# R7FA6M5BH register map
Vendor: Renesas Electronics Corporation; Series: RA6; File version: 1.20.01
CPU: CM33 r0p4, little endian, MPU, FPU, VTOR, 4 interrupt priority bits, 96 interrupts
Registers are 32-bit, read-write, reset 0x0 unless marked. A register's access mark holds for its fields unless they carry their own. Offsets are from the block's base; [hi:lo] are bit positions; {n}, {i} and the like mark numbered series; 'fields as' and 'values as' point back to an identical list.

## CANFD (part 2 of 2)
Base 0x400B0000
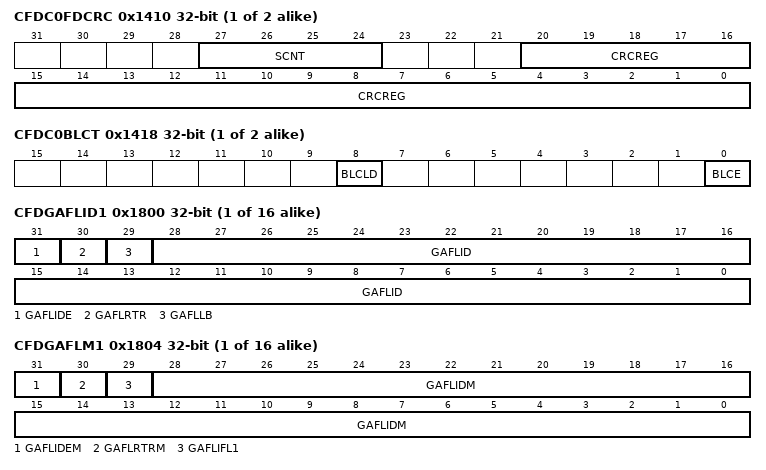
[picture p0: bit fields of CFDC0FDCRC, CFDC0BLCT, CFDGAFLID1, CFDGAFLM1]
{0x1410+0x20*i} CFDC{i}FDCRC (i=0..1) — Channel {i} CANFD CRC Register
  [27:24] SCNT ro — Stuff bit count
  [20:0] CRCREG ro — CRC Register value
{0x1418+0x20*i} CFDC{i}BLCT (i=0..1) — Channel {i} Bus Load Control Register
  [8] BLCLD wo — BUS Load Counter Load
  [0] BLCE — Bus Load Counter Enable
    0=Bus load counter disable; 1=Bus load counter enable
{0x141C+0x20*i} CFDC{i}BLSTS (i=0..1) — Channel {i} Bus Load Status Register
  [31:3] BLC ro — Bus Load Counter
{0x17F0+0x10*i} CFDGAFLID{i} (i=1..16) — Global Acceptance Filter List ID Registers
  [31] GAFLIDE — Global Acceptance Filter List Entry IDE Field
    0=Standard identifier of rule entry ID is valid for acceptance filtering; 1=Extended identifier of rule entry ID is valid for acceptance filtering
  [30] GAFLRTR — Global Acceptance Filter List Entry RTR Field
    0=Data frame; 1=Remote frame
  [29] GAFLLB — Global Acceptance Filter List Entry Loopback Configuration
    0=Global Acceptance Filter List entry ID for acceptance filtering with attribute RX; 1=Global Acceptance Filter List entry ID for acceptance filtering with attribute TX
  [28:0] GAFLID — Global Acceptance Filter List Entry ID Field
{0x17F4+0x10*i} CFDGAFLM{i} (i=1..16) — Global Acceptance Filter List Mask Registers
  [31] GAFLIDEM — Global Acceptance Filter List IDE Mask
    0=IDE bit is not used for ID matching; 1=IDE bit is used for ID matching
  [30] GAFLRTRM — Global Acceptance Filter List Entry RTR Mask
    0=RTR bit is not used for ID matching; 1=RTR bit is used for ID matching
  [29] GAFLIFL1 — Global Acceptance Filter List Information Label 1
  [28:0] GAFLIDM — Global Acceptance Filter List ID Mask Field
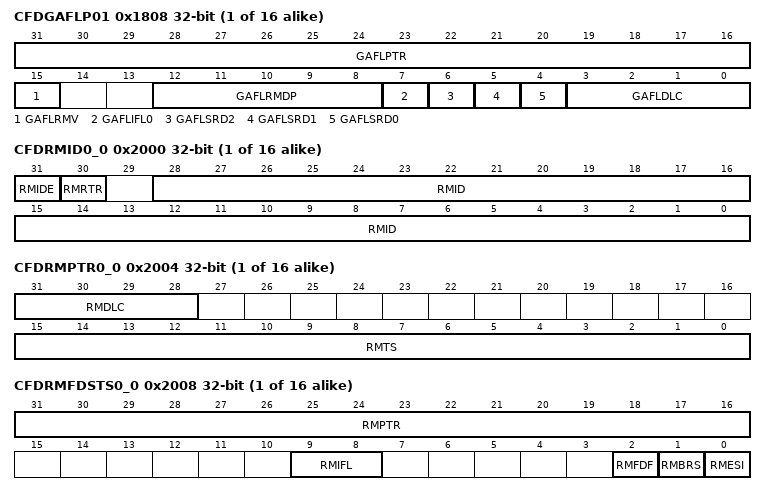
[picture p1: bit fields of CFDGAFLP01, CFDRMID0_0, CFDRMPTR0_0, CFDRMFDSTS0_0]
{0x17F8+0x10*i} CFDGAFLP0{i} (i=1..16) — Global Acceptance Filter List Pointer 0 Registers
  [31:16] GAFLPTR — Global Acceptance Filter List Pointer
  [15] GAFLRMV — Global Acceptance Filter List RX Message Buffer Valid
    0=Single message buffer direction pointer is invalid; 1=Single message buffer direction pointer is valid
  [12:8] GAFLRMDP — Global Acceptance Filter List RX Message Buffer Direction Pointer
  [7] GAFLIFL0 — Global Acceptance Filter List Information Label 0
  [6] GAFLSRD2 — Global Acceptance Filter List Select Routing Destination 2
    0=Routing target is CFIFO2; 1=Routing target is TX Queue 2 instead of CFIFO2
  [5] GAFLSRD1 — Global Acceptance Filter List Select Routing Destination 1
    0=Routing target is CFIFO1; 1=Routing target is TX Queue 1 instead of CFIFO1
  [4] GAFLSRD0 — Global Acceptance Filter List Select Routing Destination 0
    0=Routing target is CFIFO0; 1=Routing target is TX Queue 0 instead of CFIFO0
  [3:0] GAFLDLC — Global Acceptance Filter List DLC Field
{0x17FC+0x10*i} CFDGAFLP1{i} (i=1..16) — Global Acceptance Filter List Pointer 1 Registers
  [13:0] GAFLFDP — Global Acceptance Filter List FIFO Direction Pointer
{0x2000+0x80*i} CFDRMID{i}_0 (i=0..15) ro — RX Message Buffer ID Register {i} Channel 0
  [31] RMIDE — RX Message Buffer IDE Bit
    0=STD-ID is stored; 1=EXT-ID is stored
  [30] RMRTR — RX Message Buffer RTR Bit
    0=Data frame; 1=Remote frame
  [28:0] RMID — RX Message Buffer ID Field
{0x2004+0x80*i} CFDRMPTR{i}_0 (i=0..15) ro — RX Message Buffer Pointer Register {i} Channel 0
  [31:28] RMDLC — RX Message Buffer DLC Field
  [15:0] RMTS — RX Message Buffer Timestamp Field
{0x2008+0x80*i} CFDRMFDSTS{i}_0 (i=0..15) ro — RX Message Buffer CAN-FD Status Register {i} Channel 0
  [31:16] RMPTR — RX Message Buffer Pointer Field
  [9:8] RMIFL — RX Message Buffer Information Label Field
  [2] RMFDF — CAN FD Format bit
    0=Non CAN-FD frame received; 1=CAN-FD frame received
  [1] RMBRS — Bit Rate Switch bit
    0=CAN-FD frame received with no bit rate switch; 1=CAN-FD frame received with bit rate switch
  [0] RMESI — Error State Indicator bit
    0=CAN-FD frame received from error active node; 1=CAN-FD frame received from error passive node
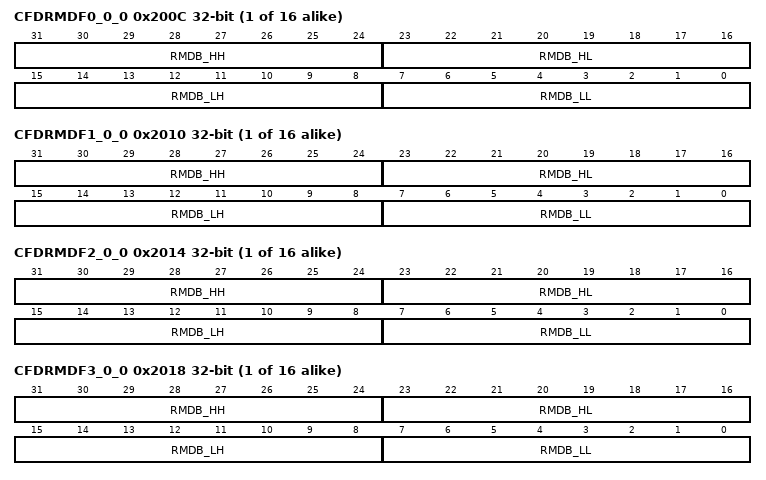
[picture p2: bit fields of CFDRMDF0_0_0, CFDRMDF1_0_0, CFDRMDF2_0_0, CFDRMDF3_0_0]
{0x200C+0x80*i} CFDRMDF0_{i}_0 (i=0..15) ro — RX Message Buffer Data Field 0 Register {i} Channel 0
  [31:24] RMDB_HH — RX Message Buffer Data Byte 3
  [23:16] RMDB_HL — RX Message Buffer Data Byte 2
  [15:8] RMDB_LH — RX Message Buffer Data Byte 1
  [7:0] RMDB_LL — RX Message Buffer Data Byte 0
{0x2010+0x80*i} CFDRMDF1_{i}_0 (i=0..15) ro — RX Message Buffer Data Field 1 Register {i} Channel 0
  [31:24] RMDB_HH — RX Message Buffer Data Byte 7
  [23:16] RMDB_HL — RX Message Buffer Data Byte 6
  [15:8] RMDB_LH — RX Message Buffer Data Byte 5
  [7:0] RMDB_LL — RX Message Buffer Data Byte 4
{0x2014+0x80*i} CFDRMDF2_{i}_0 (i=0..15) ro — RX Message Buffer Data Field 2 Register {i} Channel 0
  [31:24] RMDB_HH — RX Message Buffer Data Byte 11
  [23:16] RMDB_HL — RX Message Buffer Data Byte 10
  [15:8] RMDB_LH — RX Message Buffer Data Byte 9
  [7:0] RMDB_LL — RX Message Buffer Data Byte 8
{0x2018+0x80*i} CFDRMDF3_{i}_0 (i=0..15) ro — RX Message Buffer Data Field 3 Register {i} Channel 0
  [31:24] RMDB_HH — RX Message Buffer Data Byte 15
  [23:16] RMDB_HL — RX Message Buffer Data Byte 14
  [15:8] RMDB_LH — RX Message Buffer Data Byte 13
  [7:0] RMDB_LL — RX Message Buffer Data Byte 12
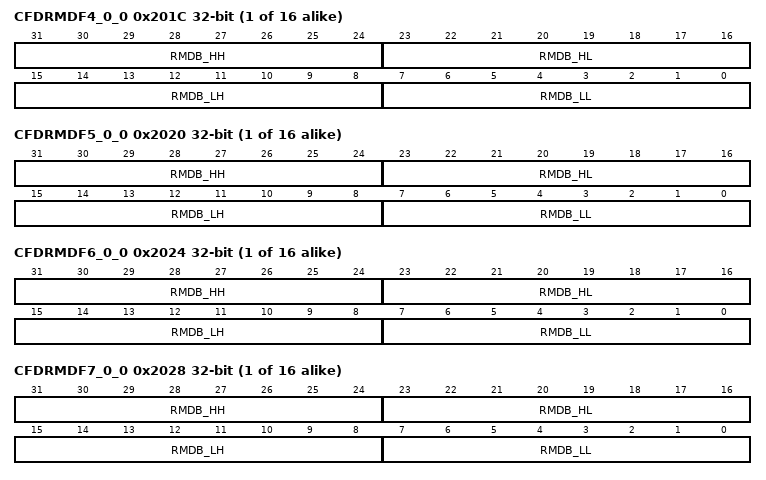
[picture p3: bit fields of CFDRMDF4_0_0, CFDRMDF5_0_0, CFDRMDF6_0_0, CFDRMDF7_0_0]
{0x201C+0x80*i} CFDRMDF4_{i}_0 (i=0..15) ro — RX Message Buffer Data Field 4 Register {i} Channel 0
  [31:24] RMDB_HH — RX Message Buffer Data Byte 19
  [23:16] RMDB_HL — RX Message Buffer Data Byte 18
  [15:8] RMDB_LH — RX Message Buffer Data Byte 17
  [7:0] RMDB_LL — RX Message Buffer Data Byte 16
{0x2020+0x80*i} CFDRMDF5_{i}_0 (i=0..15) ro — RX Message Buffer Data Field 5 Register {i} Channel 0
  [31:24] RMDB_HH — RX Message Buffer Data Byte 23
  [23:16] RMDB_HL — RX Message Buffer Data Byte 22
  [15:8] RMDB_LH — RX Message Buffer Data Byte 21
  [7:0] RMDB_LL — RX Message Buffer Data Byte 20
{0x2024+0x80*i} CFDRMDF6_{i}_0 (i=0..15) ro — RX Message Buffer Data Field 6 Register {i} Channel 0
  [31:24] RMDB_HH — RX Message Buffer Data Byte 27
  [23:16] RMDB_HL — RX Message Buffer Data Byte 26
  [15:8] RMDB_LH — RX Message Buffer Data Byte 25
  [7:0] RMDB_LL — RX Message Buffer Data Byte 24
{0x2028+0x80*i} CFDRMDF7_{i}_0 (i=0..15) ro — RX Message Buffer Data Field 7 Register {i} Channel 0
  [31:24] RMDB_HH — RX Message Buffer Data Byte 30
  [23:16] RMDB_HL — RX Message Buffer Data Byte 29
  [15:8] RMDB_LH — RX Message Buffer Data Byte 28
  [7:0] RMDB_LL — RX Message Buffer Data Byte 27
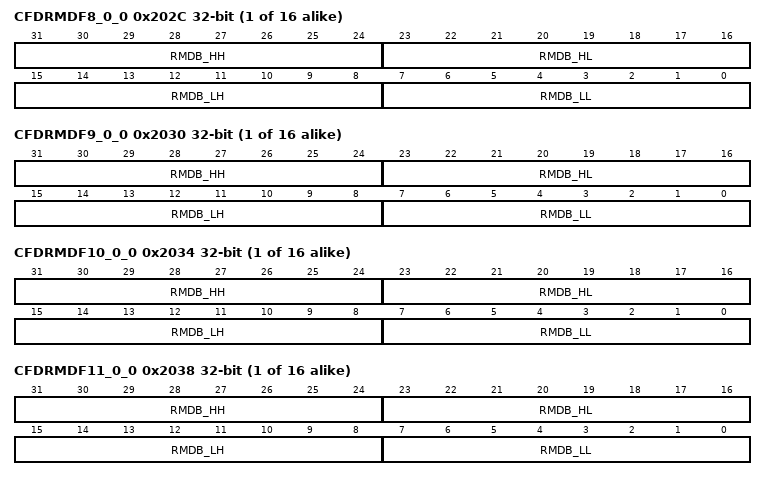
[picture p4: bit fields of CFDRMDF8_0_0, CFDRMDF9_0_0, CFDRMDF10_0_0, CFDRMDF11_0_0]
{0x202C+0x80*i} CFDRMDF8_{i}_0 (i=0..15) ro — RX Message Buffer Data Field 8 Register {i} Channel 0
  [31:24] RMDB_HH — RX Message Buffer Data Byte ((p * 4) + 3)
  [23:16] RMDB_HL — RX Message Buffer Data Byte ((p * 4) + 2)
  [15:8] RMDB_LH — RX Message Buffer Data Byte ((p * 4) + 1)
  [7:0] RMDB_LL — RX Message Buffer Data Byte (p * 4)
{0x2030+0x80*i} CFDRMDF9_{i}_0 (i=0..15) ro — RX Message Buffer Data Field 9 Register {i} Channel 0
  [31:24] RMDB_HH — RX Message Buffer Data Byte 39
  [23:16] RMDB_HL — RX Message Buffer Data Byte 38
  [15:8] RMDB_LH — RX Message Buffer Data Byte 37
  [7:0] RMDB_LL — RX Message Buffer Data Byte 36
{0x2034+0x80*i} CFDRMDF10_{i}_0 (i=0..15) ro — RX Message Buffer Data Field 10 Register {i} Channel 0
  [31:24] RMDB_HH — RX Message Buffer Data Byte 43
  [23:16] RMDB_HL — RX Message Buffer Data Byte 42
  [15:8] RMDB_LH — RX Message Buffer Data Byte 41
  [7:0] RMDB_LL — RX Message Buffer Data Byte 40
{0x2038+0x80*i} CFDRMDF11_{i}_0 (i=0..15) ro — RX Message Buffer Data Field 11 Register {i} Channel 0
  [31:24] RMDB_HH — RX Message Buffer Data Byte 47
  [23:16] RMDB_HL — RX Message Buffer Data Byte 46
  [15:8] RMDB_LH — RX Message Buffer Data Byte 45
  [7:0] RMDB_LL — RX Message Buffer Data Byte 44
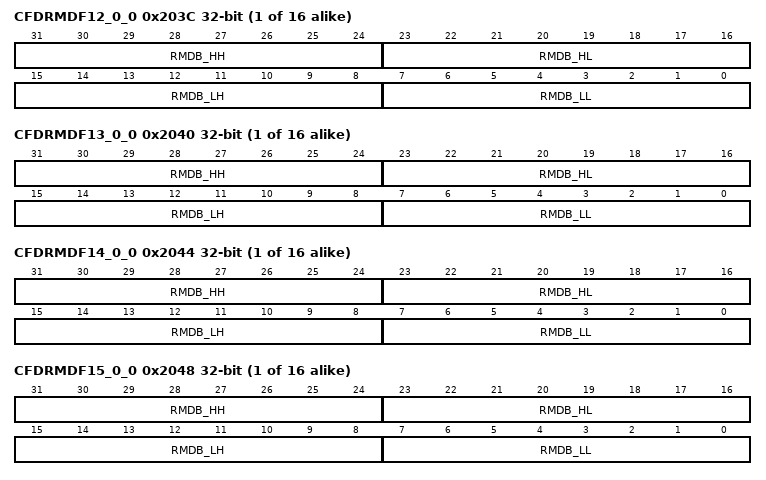
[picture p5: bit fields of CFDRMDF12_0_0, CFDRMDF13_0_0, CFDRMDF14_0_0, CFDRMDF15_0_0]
{0x203C+0x80*i} CFDRMDF12_{i}_0 (i=0..15) ro — RX Message Buffer Data Field 12 Register {i} Channel 0
  [31:24] RMDB_HH — RX Message Buffer Data Byte 51
  [23:16] RMDB_HL — RX Message Buffer Data Byte 50
  [15:8] RMDB_LH — RX Message Buffer Data Byte 49
  [7:0] RMDB_LL — RX Message Buffer Data Byte 48
{0x2040+0x80*i} CFDRMDF13_{i}_0 (i=0..15) ro — RX Message Buffer Data Field 13 Register {i} Channel 0
  [31:24] RMDB_HH — RX Message Buffer Data Byte 55
  [23:16] RMDB_HL — RX Message Buffer Data Byte 54
  [15:8] RMDB_LH — RX Message Buffer Data Byte 53
  [7:0] RMDB_LL — RX Message Buffer Data Byte 52
{0x2044+0x80*i} CFDRMDF14_{i}_0 (i=0..15) ro — RX Message Buffer Data Field 14 Register {i} Channel 0
  [31:24] RMDB_HH — RX Message Buffer Data Byte 59
  [23:16] RMDB_HL — RX Message Buffer Data Byte 58
  [15:8] RMDB_LH — RX Message Buffer Data Byte 57
  [7:0] RMDB_LL — RX Message Buffer Data Byte 56
{0x2048+0x80*i} CFDRMDF15_{i}_0 (i=0..15) ro — RX Message Buffer Data Field 15 Register {i} Channel 0
  [31:24] RMDB_HH — RX Message Buffer Data Byte 63
  [23:16] RMDB_HL — RX Message Buffer Data Byte 62
  [15:8] RMDB_LH — RX Message Buffer Data Byte 61
  [7:0] RMDB_LL — RX Message Buffer Data Byte 60
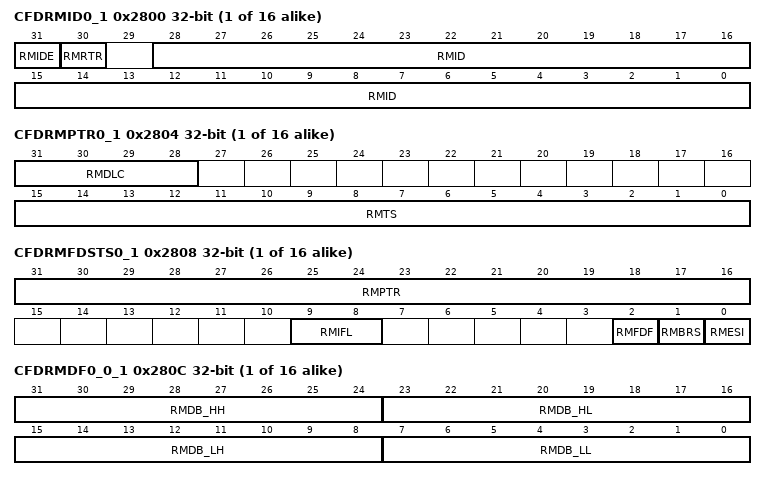
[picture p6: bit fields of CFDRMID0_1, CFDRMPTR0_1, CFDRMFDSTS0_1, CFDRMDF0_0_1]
{0x2800+0x80*i} CFDRMID{i}_1 (i=0..15) ro — RX Message Buffer ID Register {i} Channel 1
  fields as CFDRMID0_0
{0x2804+0x80*i} CFDRMPTR{i}_1 (i=0..15) ro — RX Message Buffer Pointer Register {i} Channel 1
  fields as CFDRMPTR0_0
{0x2808+0x80*i} CFDRMFDSTS{i}_1 (i=0..15) ro — RX Message Buffer CAN-FD Status Register {i} Channel 1
  fields as CFDRMFDSTS0_0
{0x280C+0x80*i} CFDRMDF0_{i}_1 (i=0..15) ro — RX Message Buffer Data Field 0 Register {i} Channel 1
  fields as CFDRMDF0_0_0
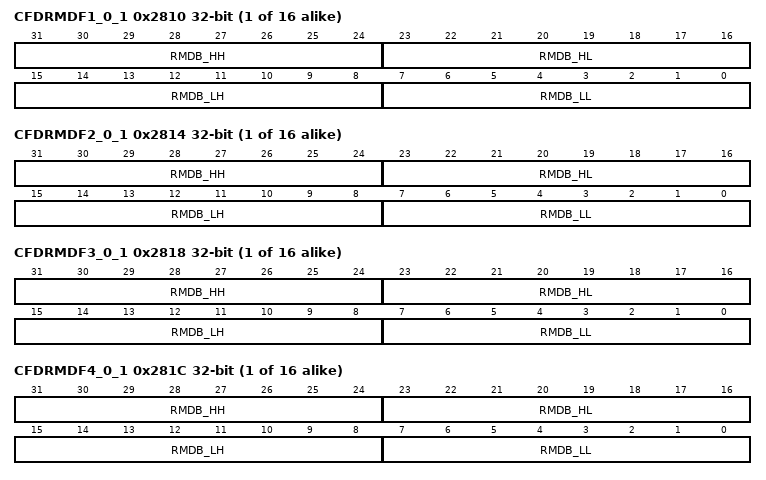
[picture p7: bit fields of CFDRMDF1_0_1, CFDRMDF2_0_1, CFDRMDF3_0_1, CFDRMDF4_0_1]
{0x2810+0x80*i} CFDRMDF1_{i}_1 (i=0..15) ro — RX Message Buffer Data Field 1 Register {i} Channel 1
  fields as CFDRMDF1_0_0
{0x2814+0x80*i} CFDRMDF2_{i}_1 (i=0..15) ro — RX Message Buffer Data Field 2 Register {i} Channel 1
  fields as CFDRMDF2_0_0
{0x2818+0x80*i} CFDRMDF3_{i}_1 (i=0..15) ro — RX Message Buffer Data Field 3 Register {i} Channel 1
  fields as CFDRMDF3_0_0
{0x281C+0x80*i} CFDRMDF4_{i}_1 (i=0..15) ro — RX Message Buffer Data Field 4 Register {i} Channel 1
  fields as CFDRMDF4_0_0
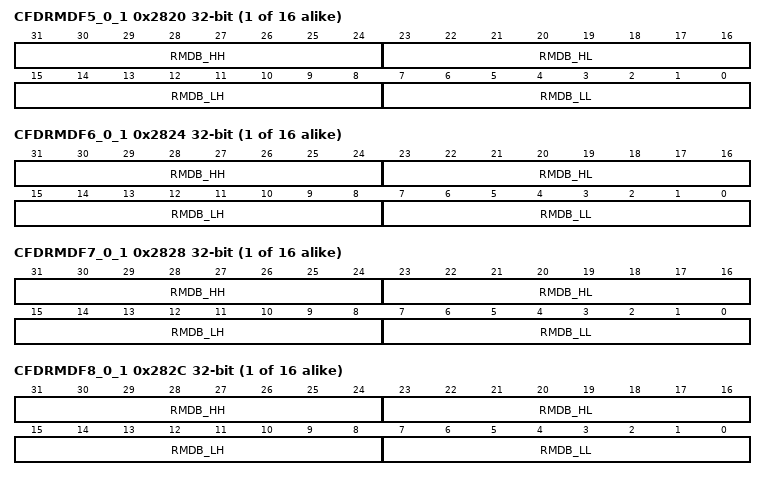
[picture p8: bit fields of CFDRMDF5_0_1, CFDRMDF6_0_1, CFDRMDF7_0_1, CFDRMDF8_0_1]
{0x2820+0x80*i} CFDRMDF5_{i}_1 (i=0..15) ro — RX Message Buffer Data Field 5 Register {i} Channel 1
  fields as CFDRMDF5_0_0
{0x2824+0x80*i} CFDRMDF6_{i}_1 (i=0..15) ro — RX Message Buffer Data Field 6 Register {i} Channel 1
  fields as CFDRMDF6_0_0
{0x2828+0x80*i} CFDRMDF7_{i}_1 (i=0..15) ro — RX Message Buffer Data Field 7 Register {i} Channel 1
  fields as CFDRMDF7_0_0
{0x282C+0x80*i} CFDRMDF8_{i}_1 (i=0..15) ro — RX Message Buffer Data Field 8 Register {i} Channel 1
  fields as CFDRMDF8_0_0
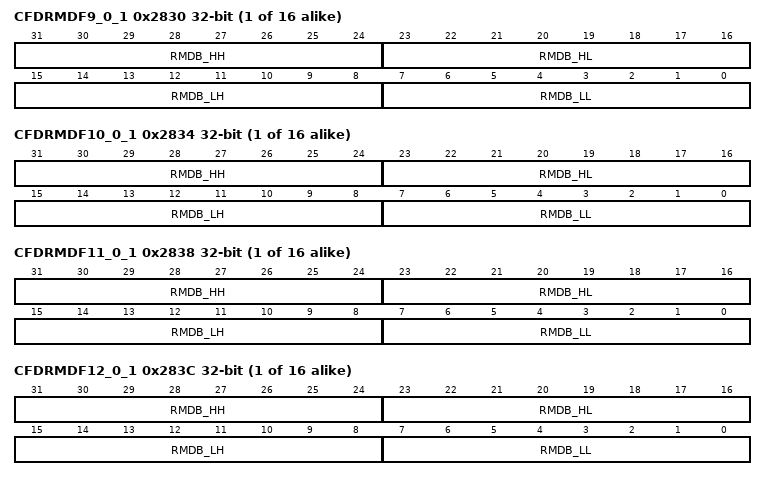
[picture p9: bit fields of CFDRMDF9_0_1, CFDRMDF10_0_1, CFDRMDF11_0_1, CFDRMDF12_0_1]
{0x2830+0x80*i} CFDRMDF9_{i}_1 (i=0..15) ro — RX Message Buffer Data Field 9 Register {i} Channel 1
  fields as CFDRMDF9_0_0
{0x2834+0x80*i} CFDRMDF10_{i}_1 (i=0..15) ro — RX Message Buffer Data Field 10 Register {i} Channel 1
  fields as CFDRMDF10_0_0
{0x2838+0x80*i} CFDRMDF11_{i}_1 (i=0..15) ro — RX Message Buffer Data Field 11 Register {i} Channel 1
  fields as CFDRMDF11_0_0
{0x283C+0x80*i} CFDRMDF12_{i}_1 (i=0..15) ro — RX Message Buffer Data Field 12 Register {i} Channel 1
  fields as CFDRMDF12_0_0
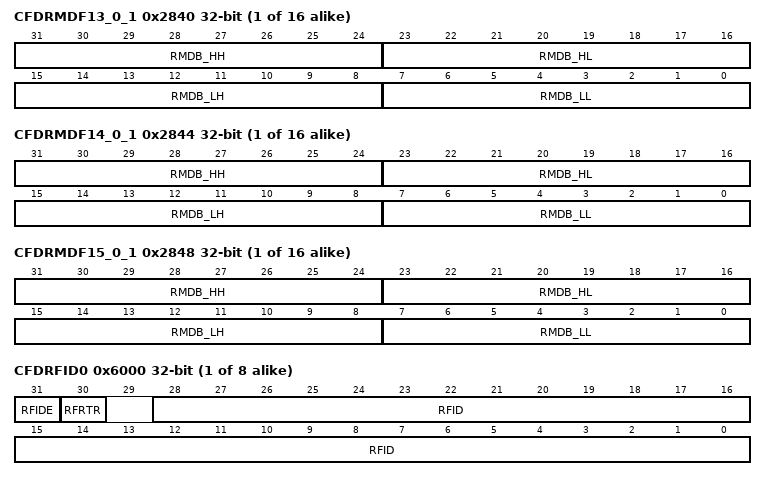
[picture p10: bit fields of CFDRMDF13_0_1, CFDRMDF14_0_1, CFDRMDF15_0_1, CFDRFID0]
{0x2840+0x80*i} CFDRMDF13_{i}_1 (i=0..15) ro — RX Message Buffer Data Field 13 Register {i} Channel 1
  fields as CFDRMDF13_0_0
{0x2844+0x80*i} CFDRMDF14_{i}_1 (i=0..15) ro — RX Message Buffer Data Field 14 Register {i} Channel 1
  fields as CFDRMDF14_0_0
{0x2848+0x80*i} CFDRMDF15_{i}_1 (i=0..15) ro — RX Message Buffer Data Field 15 Register {i} Channel 1
  fields as CFDRMDF15_0_0
{0x6000+0x80*i} CFDRFID{i} (i=0..7) ro — RX FIFO Access ID Register {i}
  [31] RFIDE — RX FIFO Buffer IDE bit
    0=STD-ID has been received; 1=EXT-ID has been received
  [30] RFRTR — RX FIFO Buffer RTR bit
    0=Data frame; 1=Remote frame
  [28:0] RFID — RX FIFO Buffer ID Field
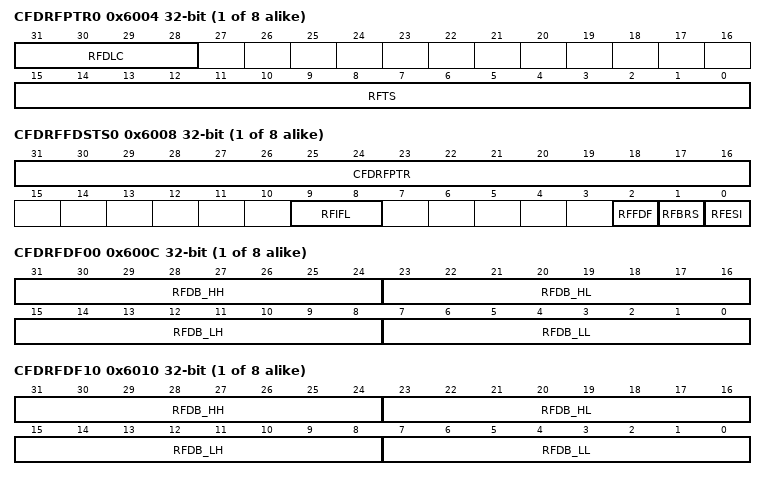
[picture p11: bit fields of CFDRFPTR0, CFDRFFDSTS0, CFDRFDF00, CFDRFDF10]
{0x6004+0x80*i} CFDRFPTR{i} (i=0..7) ro — RX FIFO Access Pointer Register {i}
  [31:28] RFDLC — RX FIFO Buffer DLC Field
  [15:0] RFTS — RX FIFO Timestamp Value
{0x6008+0x80*i} CFDRFFDSTS{i} (i=0..7) ro — RX FIFO Access CAN-FD Status Register {i}
  [31:16] CFDRFPTR — RX FIFO Buffer Pointer Field
  [9:8] RFIFL — RX FIFO Buffer Information Label Field
  [2] RFFDF — CAN FD Format bit
    0=Non CAN-FD frame received; 1=CAN-FD frame received
  [1] RFBRS — Bit Rate Switch bit
    values as CFDRMFDSTS0_0.RMBRS
  [0] RFESI — Error State Indicator bit
    values as CFDRMFDSTS0_0.RMESI
{0x600C+0x80*i} CFDRFDF0{i} (i=0..7) ro — RX FIFO Access Data Field 0 Register {i}
  [31:24] RFDB_HH — RX FIFO Buffer Data Byte 3
  [23:16] RFDB_HL — RX FIFO Buffer Data Byte 2
  [15:8] RFDB_LH — RX FIFO Buffer Data Byte 1
  [7:0] RFDB_LL — RX FIFO Buffer Data Byte 0
{0x6010+0x80*i} CFDRFDF1{i} (i=0..7) ro — RX FIFO Access Data Field 1 Register {i}
  [31:24] RFDB_HH — RX FIFO Buffer Data Byte 7
  [23:16] RFDB_HL — RX FIFO Buffer Data Byte 6
  [15:8] RFDB_LH — RX FIFO Buffer Data Byte 5
  [7:0] RFDB_LL — RX FIFO Buffer Data Byte 4
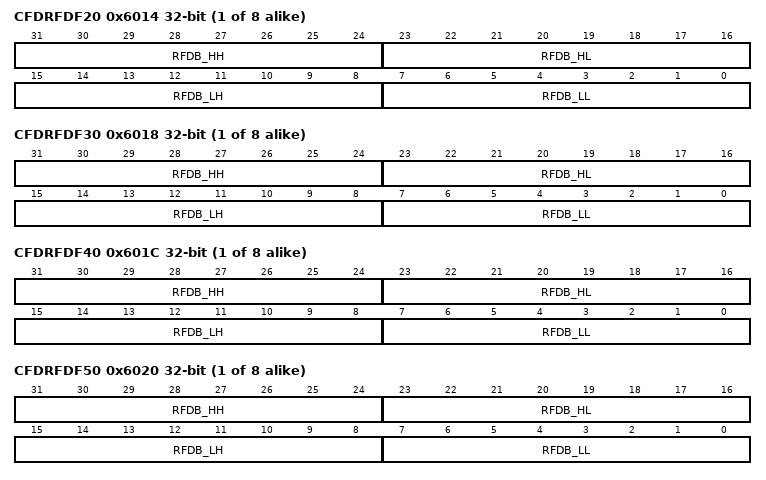
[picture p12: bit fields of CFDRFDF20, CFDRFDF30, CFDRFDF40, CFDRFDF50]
{0x6014+0x80*i} CFDRFDF2{i} (i=0..7) ro — RX FIFO Access Data Field 2 Register {i}
  [31:24] RFDB_HH — RX FIFO Buffer Data Byte 11
  [23:16] RFDB_HL — RX FIFO Buffer Data Byte 10
  [15:8] RFDB_LH — RX FIFO Buffer Data Byte 9
  [7:0] RFDB_LL — RX FIFO Buffer Data Byte 8
{0x6018+0x80*i} CFDRFDF3{i} (i=0..7) ro — RX FIFO Access Data Field 3 Register {i}
  [31:24] RFDB_HH — RX FIFO Buffer Data Byte 15
  [23:16] RFDB_HL — RX FIFO Buffer Data Byte 14
  [15:8] RFDB_LH — RX FIFO Buffer Data Byte 13
  [7:0] RFDB_LL — RX FIFO Buffer Data Byte 12
{0x601C+0x80*i} CFDRFDF4{i} (i=0..7) ro — RX FIFO Access Data Field 4 Register {i}
  [31:24] RFDB_HH — RX FIFO Buffer Data Byte 19
  [23:16] RFDB_HL — RX FIFO Buffer Data Byte 18
  [15:8] RFDB_LH — RX FIFO Buffer Data Byte 17
  [7:0] RFDB_LL — RX FIFO Buffer Data Byte 16
{0x6020+0x80*i} CFDRFDF5{i} (i=0..7) ro — RX FIFO Access Data Field 5 Register {i}
  [31:24] RFDB_HH — RX FIFO Buffer Data Byte 23
  [23:16] RFDB_HL — RX FIFO Buffer Data Byte 22
  [15:8] RFDB_LH — RX FIFO Buffer Data Byte 21
  [7:0] RFDB_LL — RX FIFO Buffer Data Byte 20
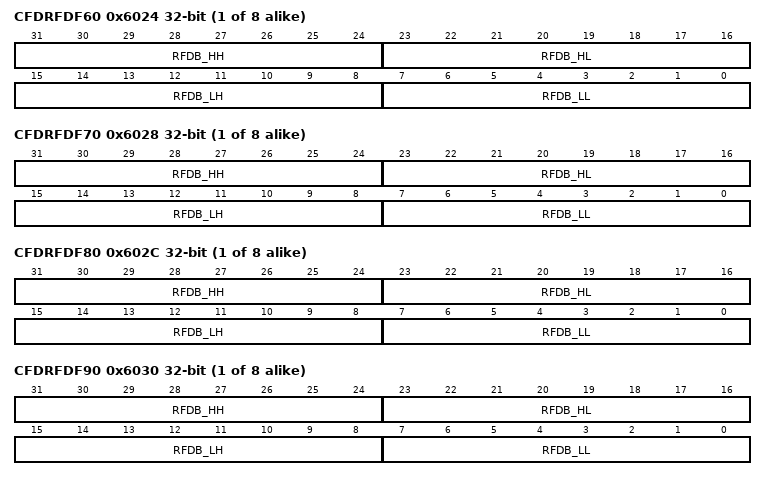
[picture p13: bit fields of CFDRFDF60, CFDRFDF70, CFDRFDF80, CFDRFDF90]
{0x6024+0x80*i} CFDRFDF6{i} (i=0..7) ro — RX FIFO Access Data Field 6 Register {i}
  [31:24] RFDB_HH — RX FIFO Buffer Data Byte 27
  [23:16] RFDB_HL — RX FIFO Buffer Data Byte 26
  [15:8] RFDB_LH — RX FIFO Buffer Data Byte 25
  [7:0] RFDB_LL — RX FIFO Buffer Data Byte 24
{0x6028+0x80*i} CFDRFDF7{i} (i=0..7) ro — RX FIFO Access Data Field 7 Register {i}
  [31:24] RFDB_HH — RX FIFO Buffer Data Byte 31
  [23:16] RFDB_HL — RX FIFO Buffer Data Byte 30
  [15:8] RFDB_LH — RX FIFO Buffer Data Byte 29
  [7:0] RFDB_LL — RX FIFO Buffer Data Byte 28
{0x602C+0x80*i} CFDRFDF8{i} (i=0..7) ro — RX FIFO Access Data Field 8 Register {i}
  [31:24] RFDB_HH — RX FIFO Buffer Data Byte 35
  [23:16] RFDB_HL — RX FIFO Buffer Data Byte 34
  [15:8] RFDB_LH — RX FIFO Buffer Data Byte 33
  [7:0] RFDB_LL — RX FIFO Buffer Data Byte 32
{0x6030+0x80*i} CFDRFDF9{i} (i=0..7) ro — RX FIFO Access Data Field 9 Register {i}
  [31:24] RFDB_HH — RX FIFO Buffer Data Byte 39
  [23:16] RFDB_HL — RX FIFO Buffer Data Byte 38
  [15:8] RFDB_LH — RX FIFO Buffer Data Byte 37
  [7:0] RFDB_LL — RX FIFO Buffer Data Byte 36
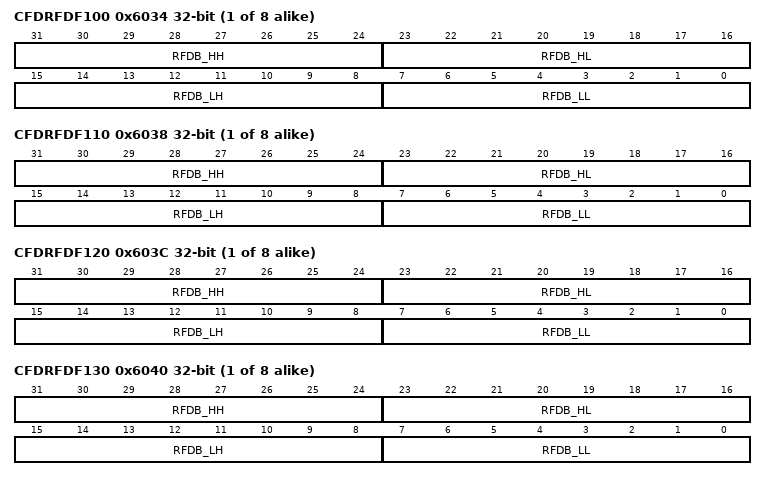
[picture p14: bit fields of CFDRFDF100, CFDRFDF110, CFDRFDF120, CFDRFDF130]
{0x6034+0x80*i} CFDRFDF10{i} (i=0..7) ro — RX FIFO Access Data Field 10 Register {i}
  [31:24] RFDB_HH — RX FIFO Buffer Data Byte 43
  [23:16] RFDB_HL — RX FIFO Buffer Data Byte 42
  [15:8] RFDB_LH — RX FIFO Buffer Data Byte 41
  [7:0] RFDB_LL — RX FIFO Buffer Data Byte 40
{0x6038+0x80*i} CFDRFDF11{i} (i=0..7) ro — RX FIFO Access Data Field 11 Register {i}
  [31:24] RFDB_HH — RX FIFO Buffer Data Byte 47
  [23:16] RFDB_HL — RX FIFO Buffer Data Byte 46
  [15:8] RFDB_LH — RX FIFO Buffer Data Byte 45
  [7:0] RFDB_LL — RX FIFO Buffer Data Byte 44
{0x603C+0x80*i} CFDRFDF12{i} (i=0..7) ro — RX FIFO Access Data Field 12 Register {i}
  [31:24] RFDB_HH — RX FIFO Buffer Data Byte 51
  [23:16] RFDB_HL — RX FIFO Buffer Data Byte 50
  [15:8] RFDB_LH — RX FIFO Buffer Data Byte 49
  [7:0] RFDB_LL — RX FIFO Buffer Data Byte 48
{0x6040+0x80*i} CFDRFDF13{i} (i=0..7) ro — RX FIFO Access Data Field 13 Register {i}
  [31:24] RFDB_HH — RX FIFO Buffer Data Byte 55
  [23:16] RFDB_HL — RX FIFO Buffer Data Byte 54
  [15:8] RFDB_LH — RX FIFO Buffer Data Byte 53
  [7:0] RFDB_LL — RX FIFO Buffer Data Byte 52
{0x6044+0x80*i} CFDRFDF14{i} (i=0..7) ro — RX FIFO Access Data Field 14 Register {i}
  [31:24] RFDB_HH — RX FIFO Buffer Data Byte 59
  [23:16] RFDB_HL — RX FIFO Buffer Data Byte 58
  [15:8] RFDB_LH — RX FIFO Buffer Data Byte 57
  [7:0] RFDB_LL — RX FIFO Buffer Data Byte 56
{0x6048+0x80*i} CFDRFDF15{i} (i=0..7) ro — RX FIFO Access Data Field 15 Register {i}
  [31:24] RFDB_HH — RX FIFO Buffer Data Byte 63
  [23:16] RFDB_HL — RX FIFO Buffer Data Byte 62
  [15:8] RFDB_LH — RX FIFO Buffer Data Byte 61
  [7:0] RFDB_LL — RX FIFO Buffer Data Byte 60
{0x6400+0x80*i} CFDCFID{i}_0 (i=0..2) — Common FIFO Access ID Register {i} Channel 0
  [31] CFIDE — Common FIFO Buffer IDE bit
    0=STD-ID is to be transmitted or has been received; 1=EXT-ID is to be transmitted or has been received
  [30] CFRTR — Common FIFO Buffer RTR bit
    0=Data frame; 1=Remote frame
  [29] THLEN — THL Entry Enable
    0=Entry is not to be stored in THL after successful TX; 1=Entry is to be stored in THL after successful TX
  [28:0] CFID — Common FIFO Buffer ID Field
{0x6404+0x80*i} CFDCFPTR{i}_0 (i=0..2) — Common FIFO Access Pointer Register {i} Channel 0
  [31:28] CFDLC — Common FIFO Buffer DLC Field
  [15:0] CFTS — Common FIFO Timestamp Value
{0x6408+0x80*i} CFDCFFDCSTS{i}_0 (i=0..2) — Common FIFO Access CAN-FD Control/Status Register {i} Channel 0
  [31:16] CFPTR — Common FIFO Buffer Pointer Field
  [9:8] CFIFL — COMMON FIFO Buffer Information Label Field
  [2] CFFDF — CAN FD Format bit
    0=Non CAN-FD frame received or to transmit; 1=CAN-FD frame received or to transmit
  [1] CFBRS — Bit Rate Switch bit
    0=CAN-FD frame received or to transmit with no bit rate switch; 1=CAN-FD frame received or to transmit with bit rate switch
  [0] CFESI — Error State Indicator bit
    0=CAN-FD frame received or to transmit by error active node; 1=CAN-FD frame received or to transmit by error passive node
{0x640C+0x80*i} CFDCFDF0{i}_0 (i=0..2) — Common FIFO Access Data Field 0 Register {i} Channel 0
  [31:24] CFDB_HH — Common FIFO Buffer Data Bytes 3
  [23:16] CFDB_HL — Common FIFO Buffer Data Bytes 2
  [15:8] CFDB_LH — Common FIFO Buffer Data Bytes 1
  [7:0] CFDB_LL — Common FIFO Buffer Data Bytes 0
{0x6410+0x80*i} CFDCFDF1{i}_0 (i=0..2) — Common FIFO Access Data Field 1 Register {i} Channel 0
  [31:24] CFDB_HH — Common FIFO Buffer Data Bytes 7
  [23:16] CFDB_HL — Common FIFO Buffer Data Bytes 6
  [15:8] CFDB_LH — Common FIFO Buffer Data Bytes 5
  [7:0] CFDB_LL — Common FIFO Buffer Data Bytes 4
{0x6414+0x80*i} CFDCFDF2{i}_0 (i=0..2) — Common FIFO Access Data Field 2 Register {i} Channel 0
  [31:24] CFDB_HH — Common FIFO Buffer Data Bytes 11
  [23:16] CFDB_HL — Common FIFO Buffer Data Bytes 10
  [15:8] CFDB_LH — Common FIFO Buffer Data Bytes 9
  [7:0] CFDB_LL — Common FIFO Buffer Data Bytes 8
{0x6418+0x80*i} CFDCFDF3{i}_0 (i=0..2) — Common FIFO Access Data Field 3 Register {i} Channel 0
  [31:24] CFDB_HH — Common FIFO Buffer Data Bytes 15
  [23:16] CFDB_HL — Common FIFO Buffer Data Bytes 14
  [15:8] CFDB_LH — Common FIFO Buffer Data Bytes 13
  [7:0] CFDB_LL — Common FIFO Buffer Data Bytes 12
{0x641C+0x80*i} CFDCFDF4{i}_0 (i=0..2) — Common FIFO Access Data Field 4 Register {i} Channel 0
  [31:24] CFDB_HH — Common FIFO Buffer Data Bytes 19
  [23:16] CFDB_HL — Common FIFO Buffer Data Bytes 18
  [15:8] CFDB_LH — Common FIFO Buffer Data Bytes 17
  [7:0] CFDB_LL — Common FIFO Buffer Data Bytes 16
{0x6420+0x80*i} CFDCFDF5{i}_0 (i=0..2) — Common FIFO Access Data Field 5 Register {i} Channel 0
  [31:24] CFDB_HH — Common FIFO Buffer Data Bytes 23
  [23:16] CFDB_HL — Common FIFO Buffer Data Bytes 22
  [15:8] CFDB_LH — Common FIFO Buffer Data Bytes 21
  [7:0] CFDB_LL — Common FIFO Buffer Data Bytes 20
{0x6424+0x80*i} CFDCFDF6{i}_0 (i=0..2) — Common FIFO Access Data Field 6 Register {i} Channel 0
  [31:24] CFDB_HH — Common FIFO Buffer Data Bytes 27
  [23:16] CFDB_HL — Common FIFO Buffer Data Bytes 26
  [15:8] CFDB_LH — Common FIFO Buffer Data Bytes 25
  [7:0] CFDB_LL — Common FIFO Buffer Data Bytes 24
{0x6428+0x80*i} CFDCFDF7{i}_0 (i=0..2) — Common FIFO Access Data Field 7 Register {i} Channel 0
  [31:24] CFDB_HH — Common FIFO Buffer Data Bytes 31
  [23:16] CFDB_HL — Common FIFO Buffer Data Bytes 30
  [15:8] CFDB_LH — Common FIFO Buffer Data Bytes 29
  [7:0] CFDB_LL — Common FIFO Buffer Data Bytes 28
{0x642C+0x80*i} CFDCFDF8{i}_0 (i=0..2) — Common FIFO Access Data Field 8 Register {i} Channel 0
  [31:24] CFDB_HH — Common FIFO Buffer Data Bytes 35
  [23:16] CFDB_HL — Common FIFO Buffer Data Bytes 34
  [15:8] CFDB_LH — Common FIFO Buffer Data Bytes 33
  [7:0] CFDB_LL — Common FIFO Buffer Data Bytes 32
{0x6430+0x80*i} CFDCFDF9{i}_0 (i=0..2) — Common FIFO Access Data Field 9 Register {i} Channel 0
  [31:24] CFDB_HH — Common FIFO Buffer Data Bytes 39
  [23:16] CFDB_HL — Common FIFO Buffer Data Bytes 38
  [15:8] CFDB_LH — Common FIFO Buffer Data Bytes 37
  [7:0] CFDB_LL — Common FIFO Buffer Data Bytes 36
{0x6434+0x80*i} CFDCFDF10{i}_0 (i=0..2) — Common FIFO Access Data Field 10 Register {i} Channel 0
  [31:24] CFDB_HH — Common FIFO Buffer Data Bytes 43
  [23:16] CFDB_HL — Common FIFO Buffer Data Bytes 42
  [15:8] CFDB_LH — Common FIFO Buffer Data Bytes 41
  [7:0] CFDB_LL — Common FIFO Buffer Data Bytes 40
{0x6438+0x80*i} CFDCFDF11{i}_0 (i=0..2) — Common FIFO Access Data Field 11 Register {i} Channel 0
  [31:24] CFDB_HH — Common FIFO Buffer Data Bytes 47
  [23:16] CFDB_HL — Common FIFO Buffer Data Bytes 46
  [15:8] CFDB_LH — Common FIFO Buffer Data Bytes 45
  [7:0] CFDB_LL — Common FIFO Buffer Data Bytes 44
{0x643C+0x80*i} CFDCFDF12{i}_0 (i=0..2) — Common FIFO Access Data Field 12 Register {i} Channel 0
  [31:24] CFDB_HH — Common FIFO Buffer Data Bytes 51
  [23:16] CFDB_HL — Common FIFO Buffer Data Bytes 50
  [15:8] CFDB_LH — Common FIFO Buffer Data Bytes 49
  [7:0] CFDB_LL — Common FIFO Buffer Data Bytes 48
{0x6440+0x80*i} CFDCFDF13{i}_0 (i=0..2) — Common FIFO Access Data Field 13 Register {i} Channel 0
  [31:24] CFDB_HH — Common FIFO Buffer Data Bytes 55
  [23:16] CFDB_HL — Common FIFO Buffer Data Bytes 54
  [15:8] CFDB_LH — Common FIFO Buffer Data Bytes 53
  [7:0] CFDB_LL — Common FIFO Buffer Data Bytes 52
{0x6444+0x80*i} CFDCFDF14{i}_0 (i=0..2) — Common FIFO Access Data Field 14 Register {i} Channel 0
  [31:24] CFDB_HH — Common FIFO Buffer Data Bytes 59
  [23:16] CFDB_HL — Common FIFO Buffer Data Bytes 58
  [15:8] CFDB_LH — Common FIFO Buffer Data Bytes 57
  [7:0] CFDB_LL — Common FIFO Buffer Data Bytes 56
{0x6448+0x80*i} CFDCFDF15{i}_0 (i=0..2) — Common FIFO Access Data Field 15 Register {i} Channel 0
  [31:24] CFDB_HH — Common FIFO Buffer Data Bytes 63
  [23:16] CFDB_HL — Common FIFO Buffer Data Bytes 62
  [15:8] CFDB_LH — Common FIFO Buffer Data Bytes 61
  [7:0] CFDB_LL — Common FIFO Buffer Data Bytes 60
{0x6580+0x80*i} CFDCFID{i}_1 (i=0..2) — Common FIFO Access ID Register {i} Channel 1
  fields as CFDCFID0_0
{0x6584+0x80*i} CFDCFPTR{i}_1 (i=0..2) — Common FIFO Access Pointer Register {i} Channel 1
  fields as CFDCFPTR0_0
{0x6588+0x80*i} CFDCFFDCSTS{i}_1 (i=0..2) — Common FIFO Access CAN-FD Control/Status Register {i} Channel 1
  fields as CFDCFFDCSTS0_0
{0x658C+0x80*i} CFDCFDF0{i}_1 (i=0..2) — Common FIFO Access Data Field 0 Register {i} Channel 1
  fields as CFDCFDF00_0
{0x6590+0x80*i} CFDCFDF1{i}_1 (i=0..2) — Common FIFO Access Data Field 1 Register {i} Channel 1
  fields as CFDCFDF10_0
{0x6594+0x80*i} CFDCFDF2{i}_1 (i=0..2) — Common FIFO Access Data Field 2 Register {i} Channel 1
  fields as CFDCFDF20_0
{0x6598+0x80*i} CFDCFDF3{i}_1 (i=0..2) — Common FIFO Access Data Field 3 Register {i} Channel 1
  fields as CFDCFDF30_0
{0x659C+0x80*i} CFDCFDF4{i}_1 (i=0..2) — Common FIFO Access Data Field 4 Register {i} Channel 1
  fields as CFDCFDF40_0
{0x65A0+0x80*i} CFDCFDF5{i}_1 (i=0..2) — Common FIFO Access Data Field 5 Register {i} Channel 1
  fields as CFDCFDF50_0
{0x65A4+0x80*i} CFDCFDF6{i}_1 (i=0..2) — Common FIFO Access Data Field 6 Register {i} Channel 1
  fields as CFDCFDF60_0
{0x65A8+0x80*i} CFDCFDF7{i}_1 (i=0..2) — Common FIFO Access Data Field 7 Register {i} Channel 1
  fields as CFDCFDF70_0
{0x65AC+0x80*i} CFDCFDF8{i}_1 (i=0..2) — Common FIFO Access Data Field 8 Register {i} Channel 1
  fields as CFDCFDF80_0
{0x65B0+0x80*i} CFDCFDF9{i}_1 (i=0..2) — Common FIFO Access Data Field 9 Register {i} Channel 1
  fields as CFDCFDF90_0
{0x65B4+0x80*i} CFDCFDF10{i}_1 (i=0..2) — Common FIFO Access Data Field 10 Register {i} Channel 1
  fields as CFDCFDF100_0
{0x65B8+0x80*i} CFDCFDF11{i}_1 (i=0..2) — Common FIFO Access Data Field 11 Register {i} Channel 1
  fields as CFDCFDF110_0
{0x65BC+0x80*i} CFDCFDF12{i}_1 (i=0..2) — Common FIFO Access Data Field 12 Register {i} Channel 1
  fields as CFDCFDF120_0
{0x65C0+0x80*i} CFDCFDF13{i}_1 (i=0..2) — Common FIFO Access Data Field 13 Register {i} Channel 1
  fields as CFDCFDF130_0
{0x65C4+0x80*i} CFDCFDF14{i}_1 (i=0..2) — Common FIFO Access Data Field 14 Register {i} Channel 1
  fields as CFDCFDF140_0
{0x65C8+0x80*i} CFDCFDF15{i}_1 (i=0..2) — Common FIFO Access Data Field 15 Register {i} Channel 1
  fields as CFDCFDF150_0
{0x8000+8i} CFDTHLACC0{i} (i=0..1) ro — TX History List Access Registers 0
  [31:16] TMTS — Transmit Timestamp
  [15] TGW — Transmit Gateway Buffer Indication
    0=No transmission from gateway; 1=Transmission from gateway
  [9:3] BN — Buffer Number
  [2:0] BT — Buffer Type
    1=Flat TX message buffer; 2=TX FIFO message buffer number and gateway FIFO message number; 4=TX Queue message buffer number
{0x8004+8i} CFDTHLACC1{i} (i=0..1) — TX History List Access Registers 1
  [17:16] TIFL ro — Transmit Information Label
  [15:0] TID ro — Transmit ID
{0x8400+4i} CFDRPGACC{i} (i=0..63) — RAM Test Page Access Registers {i}
  [31:0] RDTA — RAM Data Test Access
{0x10000+0x80*i} CFDTMID{i}_0 (i=0..7) — TX Message Buffer ID Register {i} Channel 0
  [31] TMIDE — TX Message Buffer IDE bit
    0=STD-ID is transmitted; 1=EXT-ID is transmitted
  [30] TMRTR — TX Message Buffer RTR bit
    0=Data frame; 1=Remote frame
  [29] THLEN — Tx History List Entry
    0=Entry not stored in THL after successful TX; 1=Entry stored in THL after successful TX
  [28:0] TMID — TX Message Buffer ID Field
{0x10004+0x80*i} CFDTMPTR{i}_0 (i=0..7) — TX Message Buffer Pointer Register {i} Channel 0
  [31:28] TMDLC — TX Message Buffer DLC Field
{0x10008+0x80*i} CFDTMFDCTR{i}_0 (i=0..7) — TX Message Buffer CANFD Control Register {i} Channel i
  [31:16] TMPTR — TX Message Buffer Pointer Field
  [9:8] TMIFL — TX Message Buffer Information Label Field
  [2] TMFDF — CAN FD Format bit
    0=Non CANFD frame to transmit; 1=CANFD frame to transmit
  [1] TMBRS — Bit Rate Switch bit
    0=CANFD frame to transmit with no bit rate switch; 1=CANFD frame to transmit with bit rate switch
  [0] TMESI — Error State Indicator bit
    0=CANFD frame to transmit by error active node; 1=CANFD frame to transmit by error passive node
{0x1000C+0x80*i} CFDTMDF0_{i}_0 (i=0..7) — TX Message Buffer Data Field 0 Register {i} Channel 0
  [31:24] TMDB_HH — TX Message Buffer Data Byte 3
  [23:16] TMDB_HL — TX Message Buffer Data Byte 2
  [15:8] TMDB_LH — TX Message Buffer Data Byte 1
  [7:0] TMDB_LL — TX Message Buffer Data Byte 0
{0x10010+0x80*i} CFDTMDF1_{i}_0 (i=0..7) — TX Message Buffer Data Field 1 Register {i} Channel 0
  [31:24] TMDB_HH — TX Message Buffer Data Byte 7
  [23:16] TMDB_HL — TX Message Buffer Data Byte 6
  [15:8] TMDB_LH — TX Message Buffer Data Byte 5
  [7:0] TMDB_LL — TX Message Buffer Data Byte 4
{0x10014+0x80*i} CFDTMDF2_{i}_0 (i=0..7) — TX Message Buffer Data Field 2 Register {i} Channel 0
  [31:24] TMDB_HH — TX Message Buffer Data Byte 11
  [23:16] TMDB_HL — TX Message Buffer Data Byte 10
  [15:8] TMDB_LH — TX Message Buffer Data Byte 9
  [7:0] TMDB_LL — TX Message Buffer Data Byte 8
{0x10018+0x80*i} CFDTMDF3_{i}_0 (i=0..7) — TX Message Buffer Data Field 3 Register {i} Channel 0
  [31:24] TMDB_HH — TX Message Buffer Data Byte 12
  [23:16] TMDB_HL — TX Message Buffer Data Byte 12
  [15:8] TMDB_LH — TX Message Buffer Data Byte 12
  [7:0] TMDB_LL — TX Message Buffer Data Byte 12
{0x1001C+0x80*i} CFDTMDF4_{i}_0 (i=0..7) — TX Message Buffer Data Field 4 Register {i} Channel 0
  [31:24] TMDB_HH — TX Message Buffer Data Byte 19
  [23:16] TMDB_HL — TX Message Buffer Data Byte 18
  [15:8] TMDB_LH — TX Message Buffer Data Byte 17
  [7:0] TMDB_LL — TX Message Buffer Data Byte 16
{0x10020+0x80*i} CFDTMDF5_{i}_0 (i=0..7) — TX Message Buffer Data Field 5 Register {i} Channel 0
  [31:24] TMDB_HH — TX Message Buffer Data Byte 23
  [23:16] TMDB_HL — TX Message Buffer Data Byte 22
  [15:8] TMDB_LH — TX Message Buffer Data Byte 21
  [7:0] TMDB_LL — TX Message Buffer Data Byte 20
{0x10024+0x80*i} CFDTMDF6_{i}_0 (i=0..7) — TX Message Buffer Data Field 6 Register {i} Channel 0
  [31:24] TMDB_HH — TX Message Buffer Data Byte 27
  [23:16] TMDB_HL — TX Message Buffer Data Byte 26
  [15:8] TMDB_LH — TX Message Buffer Data Byte 25
  [7:0] TMDB_LL — TX Message Buffer Data Byte 24
{0x10028+0x80*i} CFDTMDF7_{i}_0 (i=0..7) — TX Message Buffer Data Field 7 Register {i} Channel 0
  [31:24] TMDB_HH — TX Message Buffer Data Byte 31
  [23:16] TMDB_HL — TX Message Buffer Data Byte 30
  [15:8] TMDB_LH — TX Message Buffer Data Byte29
  [7:0] TMDB_LL — TX Message Buffer Data Byte 28
{0x1002C+0x80*i} CFDTMDF8_{i}_0 (i=0..7) — TX Message Buffer Data Field 8 Register {i} Channel 0
  [31:24] TMDB_HH — TX Message Buffer Data Byte 35
  [23:16] TMDB_HL — TX Message Buffer Data Byte 34
  [15:8] TMDB_LH — TX Message Buffer Data Byte 33
  [7:0] TMDB_LL — TX Message Buffer Data Byte 32
{0x10030+0x80*i} CFDTMDF9_{i}_0 (i=0..7) — TX Message Buffer Data Field 9 Register {i} Channel 0
  [31:24] TMDB_HH — TX Message Buffer Data Byte 39
  [23:16] TMDB_HL — TX Message Buffer Data Byte 38
  [15:8] TMDB_LH — TX Message Buffer Data Byte 37
  [7:0] TMDB_LL — TX Message Buffer Data Byte 36
{0x10034+0x80*i} CFDTMDF10_{i}_0 (i=0..7) — TX Message Buffer Data Field 10 Register {i} Channel 0
  [31:24] TMDB_HH — TX Message Buffer Data Byte 43
  [23:16] TMDB_HL — TX Message Buffer Data Byte 42
  [15:8] TMDB_LH — TX Message Buffer Data Byte 41
  [7:0] TMDB_LL — TX Message Buffer Data Byte 40
{0x10038+0x80*i} CFDTMDF11_{i}_0 (i=0..7) — TX Message Buffer Data Field 11 Register {i} Channel 0
  [31:24] TMDB_HH — TX Message Buffer Data Byte 47
  [23:16] TMDB_HL — TX Message Buffer Data Byte 46
  [15:8] TMDB_LH — TX Message Buffer Data Byte 45
  [7:0] TMDB_LL — TX Message Buffer Data Byte 44
{0x1003C+0x80*i} CFDTMDF12_{i}_0 (i=0..7) — TX Message Buffer Data Field 12 Register {i} Channel 0
  [31:24] TMDB_HH — TX Message Buffer Data Byte 51
  [23:16] TMDB_HL — TX Message Buffer Data Byte 50
  [15:8] TMDB_LH — TX Message Buffer Data Byte 49
  [7:0] TMDB_LL — TX Message Buffer Data Byte 48
{0x10040+0x80*i} CFDTMDF13_{i}_0 (i=0..7) — TX Message Buffer Data Field 13 Register {i} Channel 0
  [31:24] TMDB_HH — TX Message Buffer Data Byte X
  [23:16] TMDB_HL — TX Message Buffer Data Byte X
  [15:8] TMDB_LH — TX Message Buffer Data Byte X
  [7:0] TMDB_LL — TX Message Buffer Data Byte X
{0x10044+0x80*i} CFDTMDF14_{i}_0 (i=0..7) — TX Message Buffer Data Field 14 Register {i} Channel 0
  fields as CFDTMDF13_0_0
{0x10048+0x80*i} CFDTMDF15_{i}_0 (i=0..7) — TX Message Buffer Data Field X Register 15 Channel 0
  fields as CFDTMDF13_0_0
{0x10000+0x80*i} CFDTMID{i}_0 (i=32..39) — TX Message Buffer ID Register {i} Channel 0
  fields as CFDTMID0_0
{0x10004+0x80*i} CFDTMPTR{i}_0 (i=32..39) — TX Message Buffer Pointer Register {i} Channel 0
  [31:28] TMDLC — TX Message Buffer DLC Field
{0x10008+0x80*i} CFDTMFDCTR{i}_0 (i=32..39) — TX Message Buffer CANFD Control Register {i} Channel i
  fields as CFDTMFDCTR0_0
{0x1000C+0x80*i} CFDTMDF0_{i}_0 (i=32..39) — TX Message Buffer Data Field 0 Register {i} Channel 0
  fields as CFDTMDF0_0_0
{0x10010+0x80*i} CFDTMDF1_{i}_0 (i=32..39) — TX Message Buffer Data Field 1 Register {i} Channel 0
  fields as CFDTMDF1_0_0
{0x10014+0x80*i} CFDTMDF2_{i}_0 (i=32..39) — TX Message Buffer Data Field 2 Register {i} Channel 0
  fields as CFDTMDF2_0_0
{0x10018+0x80*i} CFDTMDF3_{i}_0 (i=32..39) — TX Message Buffer Data Field 3 Register {i} Channel 0
  fields as CFDTMDF3_0_0
{0x1001C+0x80*i} CFDTMDF4_{i}_0 (i=32..39) — TX Message Buffer Data Field 4 Register {i} Channel 0
  fields as CFDTMDF4_0_0
{0x10020+0x80*i} CFDTMDF5_{i}_0 (i=32..39) — TX Message Buffer Data Field 5 Register {i} Channel 0
  fields as CFDTMDF5_0_0
{0x10024+0x80*i} CFDTMDF6_{i}_0 (i=32..39) — TX Message Buffer Data Field 6 Register {i} Channel 0
  fields as CFDTMDF6_0_0
{0x10028+0x80*i} CFDTMDF7_{i}_0 (i=32..39) — TX Message Buffer Data Field 7 Register {i} Channel 0
  fields as CFDTMDF7_0_0
{0x1002C+0x80*i} CFDTMDF8_{i}_0 (i=32..39) — TX Message Buffer Data Field 8 Register {i} Channel 0
  fields as CFDTMDF8_0_0
{0x10030+0x80*i} CFDTMDF9_{i}_0 (i=32..39) — TX Message Buffer Data Field 9 Register {i} Channel 0
  fields as CFDTMDF9_0_0
{0x10034+0x80*i} CFDTMDF10_{i}_0 (i=32..39) — TX Message Buffer Data Field 10 Register {i} Channel 0
  fields as CFDTMDF10_0_0
{0x10038+0x80*i} CFDTMDF11_{i}_0 (i=32..39) — TX Message Buffer Data Field 11 Register {i} Channel 0
  fields as CFDTMDF11_0_0
{0x1003C+0x80*i} CFDTMDF12_{i}_0 (i=32..39) — TX Message Buffer Data Field 12 Register {i} Channel 0
  fields as CFDTMDF12_0_0
{0x10040+0x80*i} CFDTMDF13_{i}_0 (i=32..39) — TX Message Buffer Data Field 13 Register {i} Channel 0
  fields as CFDTMDF13_0_0
{0x10044+0x80*i} CFDTMDF14_{i}_0 (i=32..39) — TX Message Buffer Data Field 14 Register {i} Channel 0
  fields as CFDTMDF13_0_0
{0x10048+0x80*i} CFDTMDF15_{i}_0 (i=32..39) — TX Message Buffer Data Field X Register 15 Channel 0
  fields as CFDTMDF13_0_0
{0x12000+0x80*i} CFDTMID{i}_1 (i=0..7) — TX Message Buffer ID Register {i} Channel 1
  fields as CFDTMID0_0
{0x12004+0x80*i} CFDTMPTR{i}_1 (i=0..7) — TX Message Buffer Pointer Register {i} Channel 1
  [31:28] TMDLC — TX Message Buffer DLC Field
{0x12008+0x80*i} CFDTMFDCTR{i}_1 (i=0..7) — TX Message Buffer CANFD Control Register {i} Channel i
  fields as CFDTMFDCTR0_0
{0x1200C+0x80*i} CFDTMDF0_{i}_1 (i=0..7) — TX Message Buffer Data Field 0 Register {i} Channel 1
  fields as CFDTMDF0_0_0
{0x12010+0x80*i} CFDTMDF1_{i}_1 (i=0..7) — TX Message Buffer Data Field 1 Register {i} Channel 1
  fields as CFDTMDF1_0_0
{0x12014+0x80*i} CFDTMDF2_{i}_1 (i=0..7) — TX Message Buffer Data Field 2 Register {i} Channel 1
  fields as CFDTMDF2_0_0
{0x12018+0x80*i} CFDTMDF3_{i}_1 (i=0..7) — TX Message Buffer Data Field 3 Register {i} Channel 1
  fields as CFDTMDF3_0_0
{0x1201C+0x80*i} CFDTMDF4_{i}_1 (i=0..7) — TX Message Buffer Data Field 4 Register {i} Channel 1
  fields as CFDTMDF4_0_0
{0x12020+0x80*i} CFDTMDF5_{i}_1 (i=0..7) — TX Message Buffer Data Field 5 Register {i} Channel 1
  fields as CFDTMDF5_0_0
{0x12024+0x80*i} CFDTMDF6_{i}_1 (i=0..7) — TX Message Buffer Data Field 6 Register {i} Channel 1
  fields as CFDTMDF6_0_0
{0x12028+0x80*i} CFDTMDF7_{i}_1 (i=0..7) — TX Message Buffer Data Field 7 Register {i} Channel 1
  fields as CFDTMDF7_0_0
{0x1202C+0x80*i} CFDTMDF8_{i}_1 (i=0..7) — TX Message Buffer Data Field 8 Register {i} Channel 1
  fields as CFDTMDF8_0_0
{0x12030+0x80*i} CFDTMDF9_{i}_1 (i=0..7) — TX Message Buffer Data Field 9 Register {i} Channel 1
  fields as CFDTMDF9_0_0
{0x12034+0x80*i} CFDTMDF10_{i}_1 (i=0..7) — TX Message Buffer Data Field 10 Register {i} Channel 1
  fields as CFDTMDF10_0_0
{0x12038+0x80*i} CFDTMDF11_{i}_1 (i=0..7) — TX Message Buffer Data Field 11 Register {i} Channel 1
  fields as CFDTMDF11_0_0
{0x1203C+0x80*i} CFDTMDF12_{i}_1 (i=0..7) — TX Message Buffer Data Field 12 Register {i} Channel 1
  fields as CFDTMDF12_0_0
{0x12040+0x80*i} CFDTMDF13_{i}_1 (i=0..7) — TX Message Buffer Data Field 13 Register {i} Channel 1
  fields as CFDTMDF13_0_0
{0x12044+0x80*i} CFDTMDF14_{i}_1 (i=0..7) — TX Message Buffer Data Field 14 Register {i} Channel 1
  fields as CFDTMDF13_0_0
{0x12048+0x80*i} CFDTMDF15_{i}_1 (i=0..7) — TX Message Buffer Data Field X Register 15 Channel 1
  fields as CFDTMDF13_0_0
{0x12000+0x80*i} CFDTMID{i}_1 (i=32..39) — TX Message Buffer ID Register {i} Channel 1
  fields as CFDTMID0_0
{0x12004+0x80*i} CFDTMPTR{i}_1 (i=32..39) — TX Message Buffer Pointer Register {i} Channel 1
  [31:28] TMDLC — TX Message Buffer DLC Field
{0x12008+0x80*i} CFDTMFDCTR{i}_1 (i=32..39) — TX Message Buffer CANFD Control Register {i} Channel i
  fields as CFDTMFDCTR0_0
{0x1200C+0x80*i} CFDTMDF0_{i}_1 (i=32..39) — TX Message Buffer Data Field 0 Register {i} Channel 1
  fields as CFDTMDF0_0_0
{0x12010+0x80*i} CFDTMDF1_{i}_1 (i=32..39) — TX Message Buffer Data Field 1 Register {i} Channel 1
  fields as CFDTMDF1_0_0
{0x12014+0x80*i} CFDTMDF2_{i}_1 (i=32..39) — TX Message Buffer Data Field 2 Register {i} Channel 1
  fields as CFDTMDF2_0_0
{0x12018+0x80*i} CFDTMDF3_{i}_1 (i=32..39) — TX Message Buffer Data Field 3 Register {i} Channel 1
  fields as CFDTMDF3_0_0
{0x1201C+0x80*i} CFDTMDF4_{i}_1 (i=32..39) — TX Message Buffer Data Field 4 Register {i} Channel 1
  fields as CFDTMDF4_0_0
{0x12020+0x80*i} CFDTMDF5_{i}_1 (i=32..39) — TX Message Buffer Data Field 5 Register {i} Channel 1
  fields as CFDTMDF5_0_0
{0x12024+0x80*i} CFDTMDF6_{i}_1 (i=32..39) — TX Message Buffer Data Field 6 Register {i} Channel 1
  fields as CFDTMDF6_0_0
{0x12028+0x80*i} CFDTMDF7_{i}_1 (i=32..39) — TX Message Buffer Data Field 7 Register {i} Channel 1
  fields as CFDTMDF7_0_0
{0x1202C+0x80*i} CFDTMDF8_{i}_1 (i=32..39) — TX Message Buffer Data Field 8 Register {i} Channel 1
  fields as CFDTMDF8_0_0
{0x12030+0x80*i} CFDTMDF9_{i}_1 (i=32..39) — TX Message Buffer Data Field 9 Register {i} Channel 1
  fields as CFDTMDF9_0_0
{0x12034+0x80*i} CFDTMDF10_{i}_1 (i=32..39) — TX Message Buffer Data Field 10 Register {i} Channel 1
  fields as CFDTMDF10_0_0
{0x12038+0x80*i} CFDTMDF11_{i}_1 (i=32..39) — TX Message Buffer Data Field 11 Register {i} Channel 1
  fields as CFDTMDF11_0_0
{0x1203C+0x80*i} CFDTMDF12_{i}_1 (i=32..39) — TX Message Buffer Data Field 12 Register {i} Channel 1
  fields as CFDTMDF12_0_0
{0x12040+0x80*i} CFDTMDF13_{i}_1 (i=32..39) — TX Message Buffer Data Field 13 Register {i} Channel 1
  fields as CFDTMDF13_0_0
{0x12044+0x80*i} CFDTMDF14_{i}_1 (i=32..39) — TX Message Buffer Data Field 14 Register {i} Channel 1
  fields as CFDTMDF13_0_0
{0x12048+0x80*i} CFDTMDF15_{i}_1 (i=32..39) — TX Message Buffer Data Field X Register 15 Channel 1
  fields as CFDTMDF13_0_0
